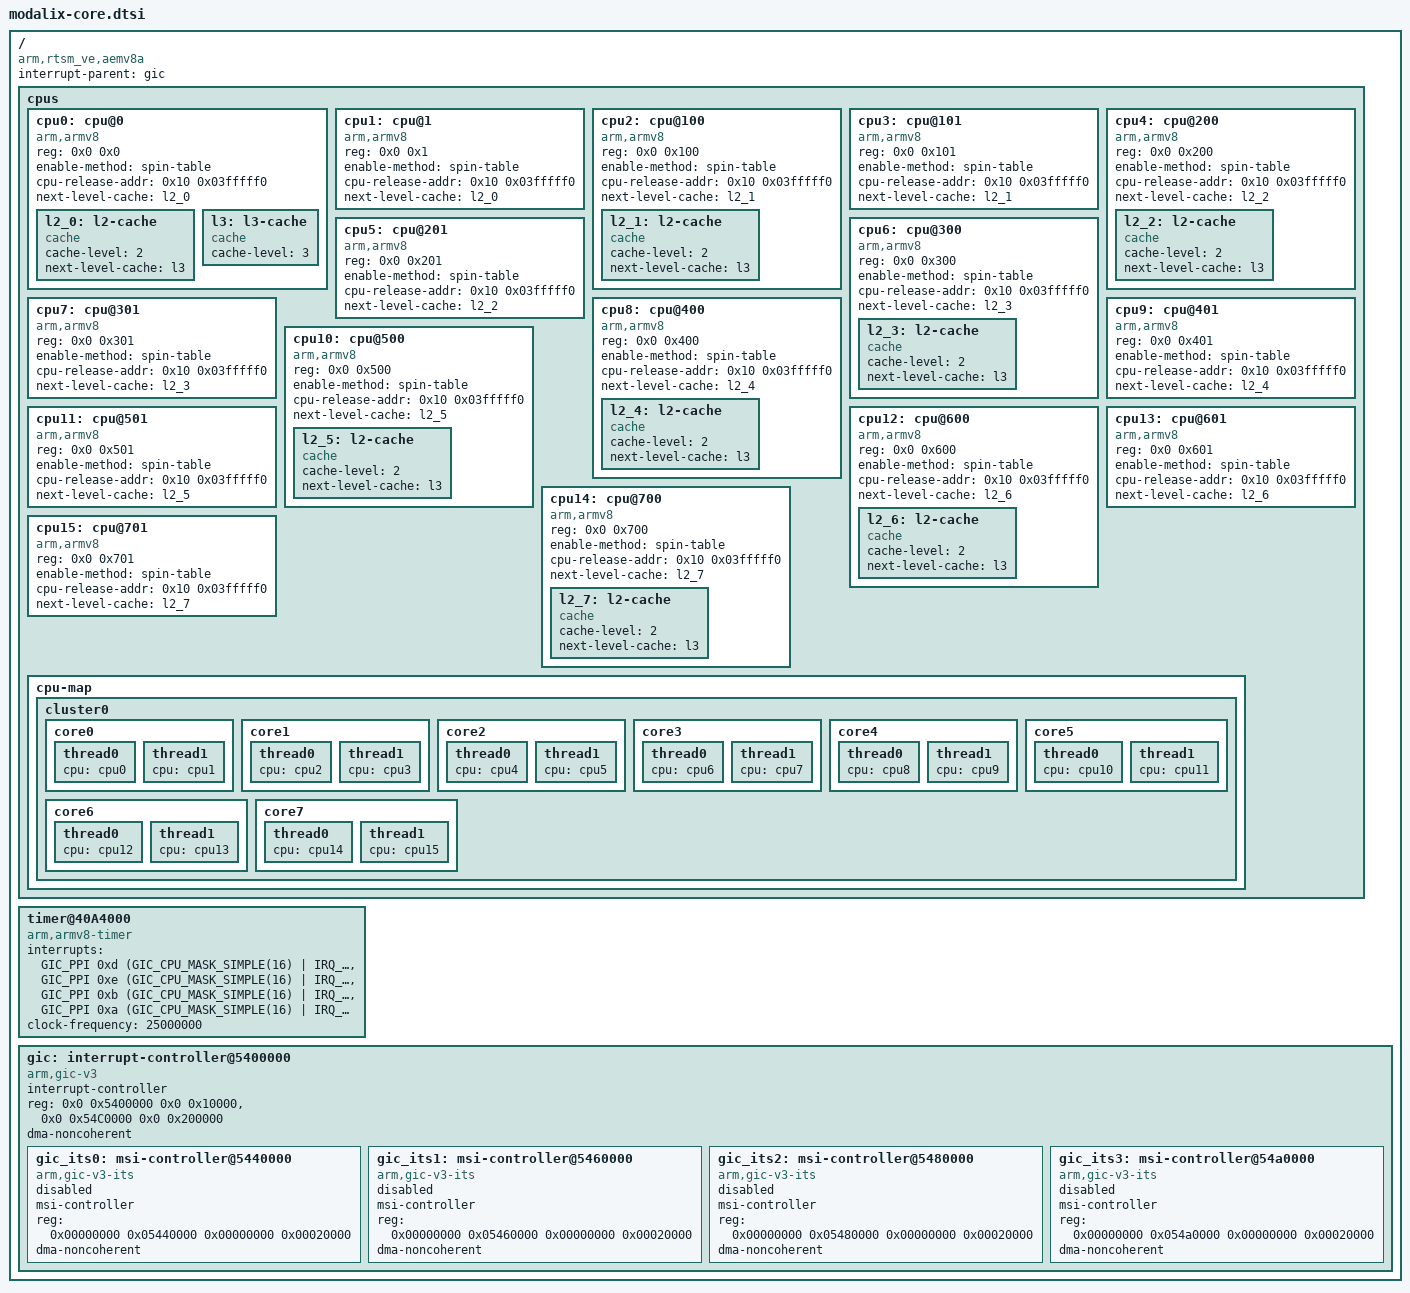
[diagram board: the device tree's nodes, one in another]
// SPDX-License-Identifier: (GPL-2.0+ OR MIT)
/*
 * Copyright (c) 2023 SiMa ai
 */

#include <dt-bindings/interrupt-controller/irq.h>
#include <dt-bindings/interrupt-controller/arm-gic.h>

/ {
	compatible = "arm,rtsm_ve,aemv8a","arm,vexpress";
	interrupt-parent = <&gic>;

	cpus {
		#address-cells = <2>;
		#size-cells = <0>;

		cpu0: cpu@0 {
			device_type = "cpu";
			compatible = "arm,armv8";
			reg = <0x0 0x0>;
			enable-method = "spin-table";
			cpu-release-addr = <0x10 0x03fffff0>;
			next-level-cache = <&l2_0>;
			l2_0: l2-cache {
				compatible = "cache";
				cache-level = <2>;
				next-level-cache = <&l3>;
			};
			l3: l3-cache {
				compatible = "cache";
				cache-level = <3>;
			};
		};

		cpu1: cpu@1 {
			device_type = "cpu";
			compatible = "arm,armv8";
			reg = <0x0 0x1>;
			enable-method = "spin-table";
			cpu-release-addr = <0x10 0x03fffff0>;
			next-level-cache = <&l2_0>;
		};

		cpu2: cpu@100 {
			device_type = "cpu";
			compatible = "arm,armv8";
			reg = <0x0 0x100>;
			enable-method = "spin-table";
			cpu-release-addr = <0x10 0x03fffff0>;
			next-level-cache = <&l2_1>;
			l2_1: l2-cache {
				compatible = "cache";
				cache-level = <2>;
				next-level-cache = <&l3>;
			};
		};

		cpu3: cpu@101 {
			device_type = "cpu";
			compatible = "arm,armv8";
			reg = <0x0 0x101>;
			enable-method = "spin-table";
			cpu-release-addr = <0x10 0x03fffff0>;
			next-level-cache = <&l2_1>;
		};

		cpu4: cpu@200 {
			device_type = "cpu";
			compatible = "arm,armv8";
			reg = <0x0 0x200>;
			enable-method = "spin-table";
			cpu-release-addr = <0x10 0x03fffff0>;
			next-level-cache = <&l2_2>;
			l2_2: l2-cache {
				compatible = "cache";
				cache-level = <2>;
				next-level-cache = <&l3>;
			};
		};

		cpu5: cpu@201 {
			device_type = "cpu";
			compatible = "arm,armv8";
			reg = <0x0 0x201>;
			enable-method = "spin-table";
			cpu-release-addr = <0x10 0x03fffff0>;
			next-level-cache = <&l2_2>;
		};

		cpu6: cpu@300 {
			device_type = "cpu";
			compatible = "arm,armv8";
			reg = <0x0 0x300>;
			enable-method = "spin-table";
			cpu-release-addr = <0x10 0x03fffff0>;
			next-level-cache = <&l2_3>;
			l2_3: l2-cache {
				compatible = "cache";
				cache-level = <2>;
				next-level-cache = <&l3>;
			};
		};

		cpu7: cpu@301 {
			device_type = "cpu";
			compatible = "arm,armv8";
			reg = <0x0 0x301>;
			enable-method = "spin-table";
			cpu-release-addr = <0x10 0x03fffff0>;
			next-level-cache = <&l2_3>;
		};

		cpu8: cpu@400 {
			device_type = "cpu";
			compatible = "arm,armv8";
			reg = <0x0 0x400>;
			enable-method = "spin-table";
			cpu-release-addr = <0x10 0x03fffff0>;
			next-level-cache = <&l2_4>;
			l2_4: l2-cache {
				compatible = "cache";
				cache-level = <2>;
				next-level-cache = <&l3>;
			};
		};

		cpu9: cpu@401 {
			device_type = "cpu";
			compatible = "arm,armv8";
			reg = <0x0 0x401>;
			enable-method = "spin-table";
			cpu-release-addr = <0x10 0x03fffff0>;
			next-level-cache = <&l2_4>;
		};

		cpu10: cpu@500 {
			device_type = "cpu";
			compatible = "arm,armv8";
			reg = <0x0 0x500>;
			enable-method = "spin-table";
			cpu-release-addr = <0x10 0x03fffff0>;
			next-level-cache = <&l2_5>;
			l2_5: l2-cache {
				compatible = "cache";
				cache-level = <2>;
				next-level-cache = <&l3>;
			};
		};

		cpu11: cpu@501 {
			device_type = "cpu";
			compatible = "arm,armv8";
			reg = <0x0 0x501>;
			enable-method = "spin-table";
			cpu-release-addr = <0x10 0x03fffff0>;
			next-level-cache = <&l2_5>;
		};

		cpu12: cpu@600 {
			device_type = "cpu";
			compatible = "arm,armv8";
			reg = <0x0 0x600>;
			enable-method = "spin-table";
			cpu-release-addr = <0x10 0x03fffff0>;
			next-level-cache = <&l2_6>;
			l2_6: l2-cache {
				compatible = "cache";
				cache-level = <2>;
				next-level-cache = <&l3>;
			};
		};

		cpu13: cpu@601 {
			device_type = "cpu";
			compatible = "arm,armv8";
			reg = <0x0 0x601>;
			enable-method = "spin-table";
			cpu-release-addr = <0x10 0x03fffff0>;
			next-level-cache = <&l2_6>;
		};

		cpu14: cpu@700 {
			device_type = "cpu";
			compatible = "arm,armv8";
			reg = <0x0 0x700>;
			enable-method = "spin-table";
			cpu-release-addr = <0x10 0x03fffff0>;
			next-level-cache = <&l2_7>;
			l2_7: l2-cache {
				compatible = "cache";
				cache-level = <2>;
				next-level-cache = <&l3>;
			};
		};

		cpu15: cpu@701 {
			device_type = "cpu";
			compatible = "arm,armv8";
			reg = <0x0 0x701>;
			enable-method = "spin-table";
			cpu-release-addr = <0x10 0x03fffff0>;
			next-level-cache = <&l2_7>;
		};

		cpu-map {
			cluster0 {
				core0 {
					thread0 {
						cpu = <&cpu0>;
					};
					thread1 {
						cpu = <&cpu1>;
					};
				};

				core1 {
					thread0 {
						cpu = <&cpu2>;
					};
					thread1 {
						cpu = <&cpu3>;
					};
				};

				core2 {
					thread0 {
						cpu = <&cpu4>;
					};
					thread1 {
						cpu = <&cpu5>;
					};
				};

				core3 {
					thread0 {
						cpu = <&cpu6>;
					};
					thread1 {
						cpu = <&cpu7>;
					};
				};

				core4 {
					thread0 {
						cpu = <&cpu8>;
					};
					thread1 {
						cpu = <&cpu9>;
					};
				};

				core5 {
					thread0 {
						cpu = <&cpu10>;
					};
					thread1 {
						cpu = <&cpu11>;
					};
				};

				core6 {
					thread0 {
						cpu = <&cpu12>;
					};
					thread1 {
						cpu = <&cpu13>;
					};
				};

				core7 {
					thread0 {
						cpu = <&cpu14>;
					};
					thread1 {
						cpu = <&cpu15>;
					};
				};
			};
		};
	};

	timer@40A4000 {
		compatible = "arm,armv8-timer";
		interrupts = <GIC_PPI 0xd (GIC_CPU_MASK_SIMPLE(16) | IRQ_TYPE_LEVEL_LOW)>,
				<GIC_PPI 0xe (GIC_CPU_MASK_SIMPLE(16) | IRQ_TYPE_LEVEL_LOW)>,
				<GIC_PPI 0xb (GIC_CPU_MASK_SIMPLE(16) | IRQ_TYPE_LEVEL_LOW)>,
				<GIC_PPI 0xa (GIC_CPU_MASK_SIMPLE(16) | IRQ_TYPE_LEVEL_LOW)>;
		clock-frequency = <25000000>;
	};

	gic: interrupt-controller@5400000 {
		compatible = "arm,gic-v3";
		#interrupt-cells = <3>;
		interrupt-controller;
		reg = <0x0 0x5400000 0x0 0x10000>,
			<0x0 0x54C0000 0x0 0x200000>;
		#address-cells = <2>;
		#size-cells = <2>;
		ranges;
		dma-noncoherent;

		gic_its0: msi-controller@5440000 {
			compatible = "arm,gic-v3-its";
			msi-controller;
			reg = <0x00000000 0x05440000 0x00000000 0x00020000>;
			dma-noncoherent;
			status = "disabled";
		};

		gic_its1: msi-controller@5460000 {
			compatible = "arm,gic-v3-its";
			msi-controller;
			reg = <0x00000000 0x05460000 0x00000000 0x00020000>;
			dma-noncoherent;
			status = "disabled";
		};

		gic_its2: msi-controller@5480000 {
			compatible = "arm,gic-v3-its";
			msi-controller;
			reg = <0x00000000 0x05480000 0x00000000 0x00020000>;
			dma-noncoherent;
			status = "disabled";
		};

		gic_its3: msi-controller@54a0000 {
			compatible = "arm,gic-v3-its";
			msi-controller;
			reg = <0x00000000 0x054a0000 0x00000000 0x00020000>;
			dma-noncoherent;
			status = "disabled";
		};
	};
};
